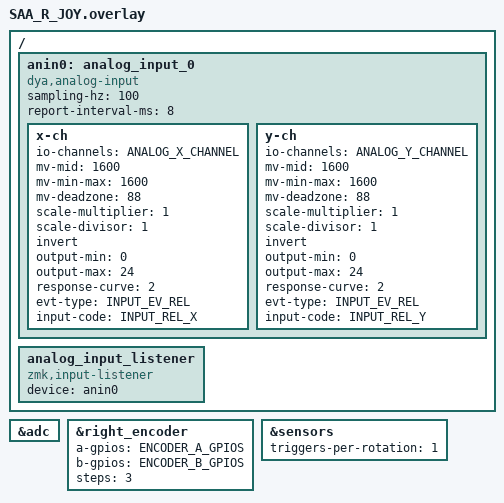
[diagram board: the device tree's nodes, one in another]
#include "SAA_pins.dtsi"

&adc {
    status = "okay";
};

&right_encoder {
    a-gpios = ENCODER_A_GPIOS;
    b-gpios = ENCODER_B_GPIOS;
    steps = <3>;
    status = "okay";
};

&sensors {
    triggers-per-rotation = <1>;
};

/ {
    anin0: analog_input_0 {
        compatible = "dya,analog-input";
        sampling-hz = <100>;
        report-interval-ms = <8>;
        x-ch {
            io-channels = ANALOG_X_CHANNEL;
            mv-mid = <1600>;
            mv-min-max = <1600>;
            mv-deadzone = <88>;
            scale-multiplier = <1>;
            scale-divisor = <1>;
            invert;
            output-min = <0>;
            output-max = <24>;
            response-curve = <2>;
            evt-type = <INPUT_EV_REL>;
            input-code = <INPUT_REL_X>;
        };
        y-ch {
            io-channels = ANALOG_Y_CHANNEL;
            mv-mid = <1600>;
            mv-min-max = <1600>;
            mv-deadzone = <88>;
            scale-multiplier = <1>;
            scale-divisor = <1>;
            invert;
            output-min = <0>;
            output-max = <24>;
            response-curve = <2>;
            evt-type = <INPUT_EV_REL>;
            input-code = <INPUT_REL_Y>;
        };
    };

    analog_input_listener: analog_input_listener {
        compatible = "zmk,input-listener";
        status = "okay";
        device = <&anin0>;
    };
};
